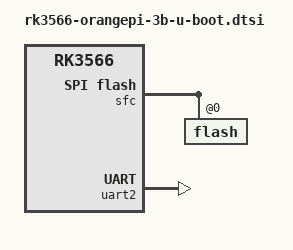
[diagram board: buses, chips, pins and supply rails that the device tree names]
// SPDX-License-Identifier: GPL-2.0+

#include "rk356x-u-boot.dtsi"

/ {
	chosen {
		stdout-path = &uart2;
	};
};

&sfc {
	bootph-pre-ram;
	u-boot,spl-sfc-no-dma;

	flash@0 {
		bootph-pre-ram;
	};
};

&uart2 {
	bootph-all;
	clock-frequency = <24000000>;
	status = "okay";
};
